AUTOSAR XML (schema 4-2-2)
package /AUTOSAR_WdgM
  data type mapping set WdgM_Type_Map: mode-request-type-map{implementation-data-type=uint8, mode-group=WdgM_Mode}
  mode declaration group WdgM_Mode: category=EXPLICIT_ORDER, initial-mode=SUPERVISION_OK, on-transition-value=255
    5 x mode:
      SUPERVISION_OK: value=0
      SUPERVISION_FAILED: value=1
      SUPERVISION_EXPIRED: value=2
      SUPERVISION_STOPPED: value=3
      SUPERVISION_DEACTIVATED: value=4
  client server interface WdgM_AliveSupervision: is-service=true
    operation CheckpointReached: possible-error=E_NOT_OK
      arg CheckpointID: type=WdgM_CheckpointIdType, direction=IN
    error E_NOT_OK: error-code=1
  mode switch interface WdgM_IndividualMode: is-service=true
    mode group currentMode: type=WdgM_Mode
  mode switch interface WdgM_GlobalMode: is-service=true
    mode group currentMode: type=WdgM_Mode
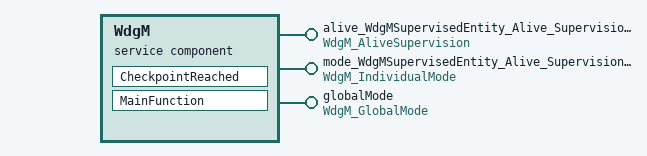
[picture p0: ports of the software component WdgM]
  service sw component type WdgM
    provide port alive_WdgMSupervisedEntity_Alive_Supervision_Entity1: server-com-spec{operation=CheckpointReached, queue-length=2}, provided-interface=WdgM_AliveSupervision
    provide port mode_WdgMSupervisedEntity_Alive_Supervision_Entity1: mode-switch-sender-com-spec{mode-group=currentMode, mode-switched-ack=timeout=1.0, queue-length=1}, provided-interface=WdgM_IndividualMode
    provide port globalMode: mode-switch-sender-com-spec{mode-group=currentMode, mode-switched-ack=timeout=1.0, queue-length=1}, provided-interface=WdgM_GlobalMode
    behavior WdgM_InternalBehaviour: data-type-mapping=WdgM_Type_Map
      operation invoked event OIE_CheckpointReached_WdgMSupervisedEntity_Alive_Supervision_Entity1: start-on-event=CheckpointReached, operation=alive_WdgMSupervisedEntity_Alive_Supervision_Entity1.CheckpointReached
      port-api-options:
        {enable-take-address=false, indirect-api=false, port-defined-argument-value{value=0, value-type=WdgM_SupervisedEntityIdType}, port=alive_WdgMSupervisedEntity_Alive_Supervision_Entity1}
        indirect-api=true, port=mode_WdgMSupervisedEntity_Alive_Supervision_Entity1
        enable-take-address=true, indirect-api=false, port=globalMode
      runnable CheckpointReached: can-be-invoked-concurrently=true, symbol=WdgM_CheckpointReached
      runnable MainFunction: symbol=WdgM_MainFunction
        mode switch point msp_WdgM_IndividualMode_WdgMSupervisedEntity_Alive_Supervision_Entity1: mode-group=mode_WdgMSupervisedEntity_Alive_Supervision_Entity1.currentMode
        mode switch point msp_WdgM_GlobalMode: mode-group=globalMode.currentMode
